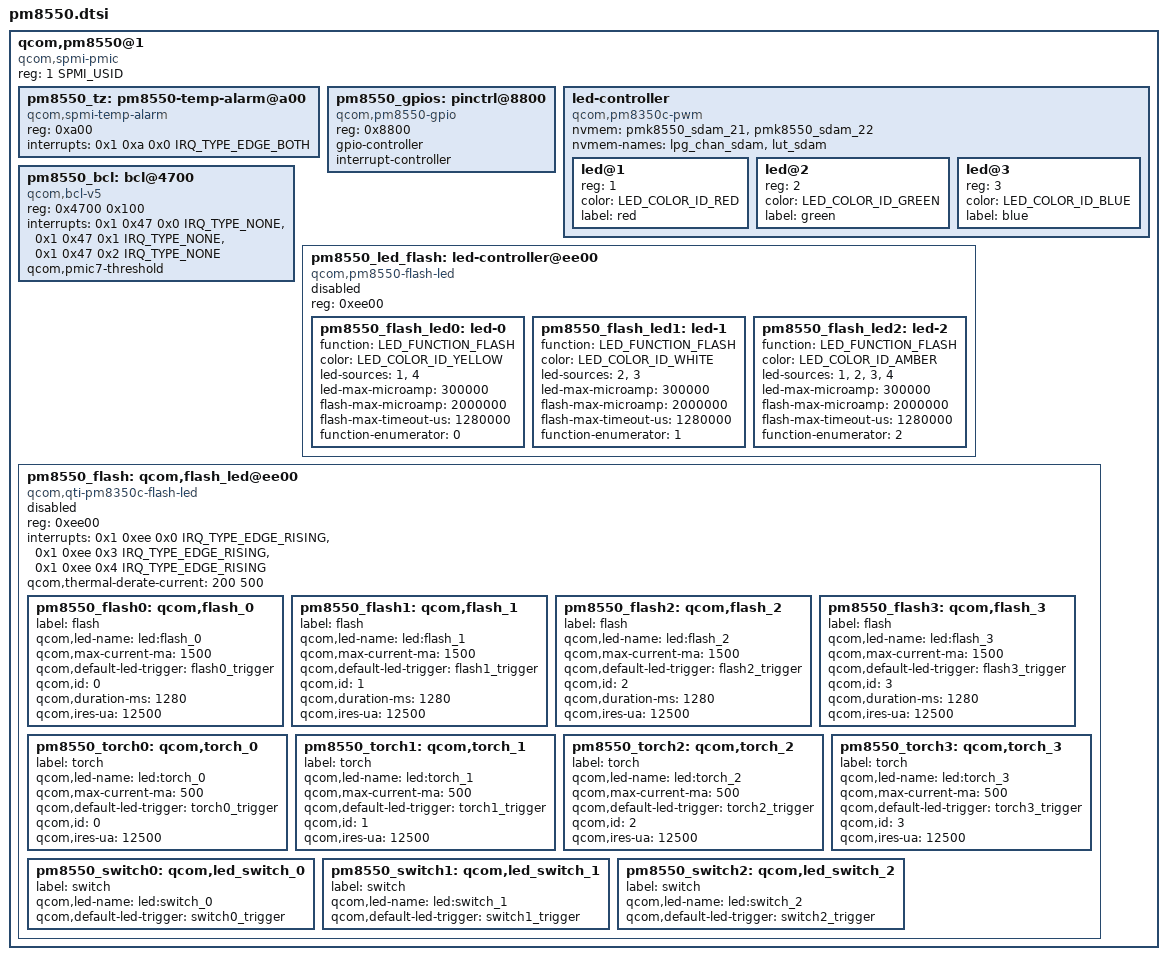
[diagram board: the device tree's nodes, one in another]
// SPDX-License-Identifier: BSD-3-Clause
/*
 * Copyright (c) 2022-2025 Qualcomm Innovation Center, Inc. All rights reserved.
 */

#include <dt-bindings/interrupt-controller/irq.h>
#include <dt-bindings/leds/common.h>
#include <dt-bindings/spmi/spmi.h>

qcom,pm8550@1 {
	compatible = "qcom,spmi-pmic";
	reg = <1 SPMI_USID>;
	#address-cells = <1>;
	#size-cells = <0>;

	pm8550_tz: pm8550-temp-alarm@a00 {
		compatible = "qcom,spmi-temp-alarm";
		reg = <0xa00>;
		interrupts = <0x1 0xa 0x0 IRQ_TYPE_EDGE_BOTH>;
		#thermal-sensor-cells = <0>;
	};

	pm8550_gpios: pinctrl@8800 {
		compatible = "qcom,pm8550-gpio";
		reg = <0x8800>;
		gpio-controller;
		#gpio-cells = <2>;
		interrupt-controller;
		#interrupt-cells = <2>;
	};

	led-controller {
		compatible = "qcom,pm8350c-pwm";
		#address-cells = <1>;
		#size-cells = <0>;
		#pwm-cells = <2>;
		nvmem = <&pmk8550_sdam_21>, <&pmk8550_sdam_22>;
		nvmem-names = "lpg_chan_sdam", "lut_sdam";

		led@1 {
			reg = <1>;
			color = <LED_COLOR_ID_RED>;
			label = "red";
		};

		led@2 {
			reg = <2>;
			color = <LED_COLOR_ID_GREEN>;
			label = "green";
		};

		led@3 {
			reg = <3>;
			color = <LED_COLOR_ID_BLUE>;
			label = "blue";
		};
	};

	pm8550_bcl: bcl@4700 {
		compatible = "qcom,bcl-v5";
		reg = <0x4700 0x100>;
		interrupts = <0x1 0x47 0x0 IRQ_TYPE_NONE>,
			     <0x1 0x47 0x1 IRQ_TYPE_NONE>,
			     <0x1 0x47 0x2 IRQ_TYPE_NONE>;
		interrupt-names = "bcl-lvl0",
				  "bcl-lvl1",
				  "bcl-lvl2";
		qcom,pmic7-threshold;
		#thermal-sensor-cells = <1>;
	};

	pm8550_led_flash: led-controller@ee00 {
		compatible = "qcom,pm8550-flash-led", "qcom,spmi-flash-led";
		reg = <0xee00>;
		status = "disabled";

		pm8550_flash_led0: led-0 {
			function = LED_FUNCTION_FLASH;
			color = <LED_COLOR_ID_YELLOW>;
			led-sources = <1>, <4>;
			led-max-microamp = <300000>;
			flash-max-microamp = <2000000>;
			flash-max-timeout-us = <1280000>;
			function-enumerator = <0>;
		};

		pm8550_flash_led1: led-1 {
			function = LED_FUNCTION_FLASH;
			color = <LED_COLOR_ID_WHITE>;
			led-sources = <2>, <3>;
			led-max-microamp = <300000>;
			flash-max-microamp = <2000000>;
			flash-max-timeout-us = <1280000>;
			function-enumerator = <1>;
		};

		pm8550_flash_led2: led-2 {
			function = LED_FUNCTION_FLASH;
			color = <LED_COLOR_ID_AMBER>;
			led-sources = <1>, <2>, <3>, <4>;
			led-max-microamp = <300000>;
			flash-max-microamp = <2000000>;
			flash-max-timeout-us = <1280000>;
			function-enumerator = <2>;
		};
	};

	pm8550_flash: qcom,flash_led@ee00 {
		compatible = "qcom,qti-pm8350c-flash-led";
		reg = <0xee00>;
		interrupts = <0x1 0xee 0x0 IRQ_TYPE_EDGE_RISING>,
			     <0x1 0xee 0x3 IRQ_TYPE_EDGE_RISING>,
			     <0x1 0xee 0x4 IRQ_TYPE_EDGE_RISING>;
		interrupt-names = "led-fault-irq",
				  "all-ramp-down-done-irq",
				  "all-ramp-up-done-irq";
		qcom,thermal-derate-current = <200 500>;
		status = "disabled";

		pm8550_flash0: qcom,flash_0 {
			label = "flash";
			qcom,led-name = "led:flash_0";
			qcom,max-current-ma = <1500>;
			qcom,default-led-trigger = "flash0_trigger";
			qcom,id = <0>;
			qcom,duration-ms = <1280>;
			qcom,ires-ua = <12500>;
		};

		pm8550_flash1: qcom,flash_1 {
			label = "flash";
			qcom,led-name = "led:flash_1";
			qcom,max-current-ma = <1500>;
			qcom,default-led-trigger = "flash1_trigger";
			qcom,id = <1>;
			qcom,duration-ms = <1280>;
			qcom,ires-ua = <12500>;
		};

		pm8550_flash2: qcom,flash_2 {
			label = "flash";
			qcom,led-name = "led:flash_2";
			qcom,max-current-ma = <1500>;
			qcom,default-led-trigger = "flash2_trigger";
			qcom,id = <2>;
			qcom,duration-ms = <1280>;
			qcom,ires-ua = <12500>;
		};

		pm8550_flash3: qcom,flash_3 {
			label = "flash";
			qcom,led-name = "led:flash_3";
			qcom,max-current-ma = <1500>;
			qcom,default-led-trigger = "flash3_trigger";
			qcom,id = <3>;
			qcom,duration-ms = <1280>;
			qcom,ires-ua = <12500>;
		};

		pm8550_torch0: qcom,torch_0 {
			label = "torch";
			qcom,led-name = "led:torch_0";
			qcom,max-current-ma = <500>;
			qcom,default-led-trigger = "torch0_trigger";
			qcom,id = <0>;
			qcom,ires-ua = <12500>;
		};

		pm8550_torch1: qcom,torch_1 {
			label = "torch";
			qcom,led-name = "led:torch_1";
			qcom,max-current-ma = <500>;
			qcom,default-led-trigger = "torch1_trigger";
			qcom,id = <1>;
			qcom,ires-ua = <12500>;
		};

		pm8550_torch2: qcom,torch_2 {
			label = "torch";
			qcom,led-name = "led:torch_2";
			qcom,max-current-ma = <500>;
			qcom,default-led-trigger = "torch2_trigger";
			qcom,id = <2>;
			qcom,ires-ua = <12500>;
		};

		pm8550_torch3: qcom,torch_3 {
			label = "torch";
			qcom,led-name = "led:torch_3";
			qcom,max-current-ma = <500>;
			qcom,default-led-trigger = "torch3_trigger";
			qcom,id = <3>;
			qcom,ires-ua = <12500>;
		};

		pm8550_switch0: qcom,led_switch_0 {
			label = "switch";
			qcom,led-name = "led:switch_0";
			qcom,default-led-trigger = "switch0_trigger";
		};

		pm8550_switch1: qcom,led_switch_1 {
			label = "switch";
			qcom,led-name = "led:switch_1";
			qcom,default-led-trigger = "switch1_trigger";
		};

		pm8550_switch2: qcom,led_switch_2 {
			label = "switch";
			qcom,led-name = "led:switch_2";
			qcom,default-led-trigger = "switch2_trigger";
		};
	};
};
